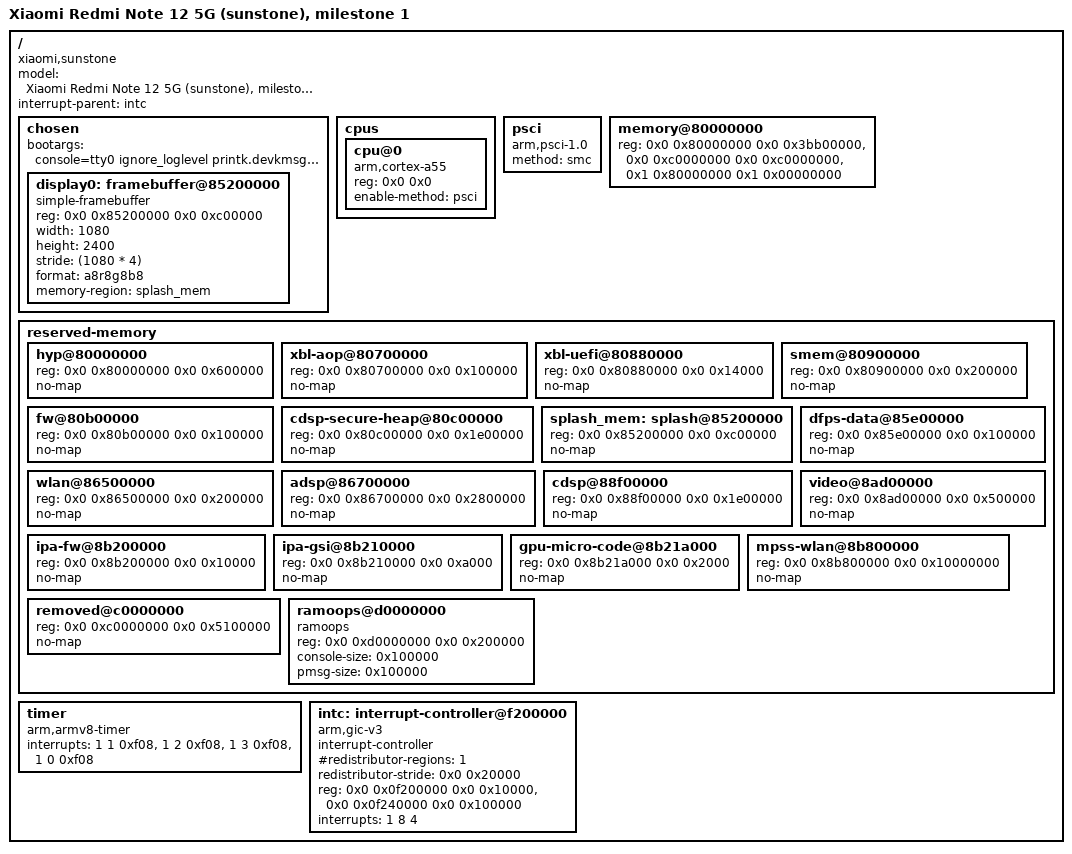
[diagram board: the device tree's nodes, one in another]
// SPDX-License-Identifier: BSD-3-Clause
/*
 * Xiaomi Redmi Note 12 5G (sunstone), SM4375 "blair": milestone 1 tree.
 *
 * Deliberately standalone (no sm6375.dtsi): one CPU, the GIC, the arch timer, RAM, the
 * firmware carve-outs, ABL's splash framebuffer and ramoops. No clock, power-domain or
 * regulator providers, so nothing switches off what the bootloader left running (the
 * panel keeps scanning the splash buffer). Values from the phone's live DT (2026-10-20).
 */
/dts-v1/;

/ {
	model = "Xiaomi Redmi Note 12 5G (sunstone), milestone 1";
	compatible = "xiaomi,sunstone", "qcom,sm4375";
	#address-cells = <2>;
	#size-cells = <2>;
	interrupt-parent = <&intc>;

	chosen {
		#address-cells = <2>;
		#size-cells = <2>;
		ranges;
		bootargs = "console=tty0 ignore_loglevel printk.devkmsg=on panic=20 reboot=warm rdinit=/init";

		display0: framebuffer@85200000 {
			compatible = "simple-framebuffer";
			reg = <0x0 0x85200000 0x0 0xc00000>;
			width = <1080>;
			height = <2400>;
			stride = <(1080 * 4)>;
			format = "a8r8g8b8";
			memory-region = <&splash_mem>;
		};
	};

	cpus {
		#address-cells = <2>;
		#size-cells = <0>;

		cpu@0 {
			device_type = "cpu";
			compatible = "arm,cortex-a55";
			reg = <0x0 0x0>;
			enable-method = "psci";
		};
	};

	psci {
		compatible = "arm,psci-1.0";
		method = "smc";
	};

	memory@80000000 {
		device_type = "memory";
		reg = <0x0 0x80000000 0x0 0x3bb00000>,
		      <0x0 0xc0000000 0x0 0xc0000000>,
		      <0x1 0x80000000 0x1 0x00000000>;
	};

	reserved-memory {
		#address-cells = <2>;
		#size-cells = <2>;
		ranges;

		hyp@80000000 { reg = <0x0 0x80000000 0x0 0x600000>; no-map; };
		xbl-aop@80700000 { reg = <0x0 0x80700000 0x0 0x100000>; no-map; };
		xbl-uefi@80880000 { reg = <0x0 0x80880000 0x0 0x14000>; no-map; };
		smem@80900000 { reg = <0x0 0x80900000 0x0 0x200000>; no-map; };
		fw@80b00000 { reg = <0x0 0x80b00000 0x0 0x100000>; no-map; };
		cdsp-secure-heap@80c00000 { reg = <0x0 0x80c00000 0x0 0x1e00000>; no-map; };
		splash_mem: splash@85200000 { reg = <0x0 0x85200000 0x0 0xc00000>; no-map; };
		dfps-data@85e00000 { reg = <0x0 0x85e00000 0x0 0x100000>; no-map; };
		wlan@86500000 { reg = <0x0 0x86500000 0x0 0x200000>; no-map; };
		adsp@86700000 { reg = <0x0 0x86700000 0x0 0x2800000>; no-map; };
		cdsp@88f00000 { reg = <0x0 0x88f00000 0x0 0x1e00000>; no-map; };
		video@8ad00000 { reg = <0x0 0x8ad00000 0x0 0x500000>; no-map; };
		ipa-fw@8b200000 { reg = <0x0 0x8b200000 0x0 0x10000>; no-map; };
		ipa-gsi@8b210000 { reg = <0x0 0x8b210000 0x0 0xa000>; no-map; };
		gpu-micro-code@8b21a000 { reg = <0x0 0x8b21a000 0x0 0x2000>; no-map; };
		mpss-wlan@8b800000 { reg = <0x0 0x8b800000 0x0 0x10000000>; no-map; };
		removed@c0000000 { reg = <0x0 0xc0000000 0x0 0x5100000>; no-map; };

		/* the downstream kernel's layout, so either kernel reads the other's records */
		ramoops@d0000000 {
			compatible = "ramoops";
			reg = <0x0 0xd0000000 0x0 0x200000>;
			console-size = <0x100000>;
			pmsg-size = <0x100000>;
		};
	};

	timer {
		compatible = "arm,armv8-timer";
		/* secure phys, non-secure phys, virtual, hypervisor PPIs; level low */
		interrupts = <1 1 0xf08>, <1 2 0xf08>, <1 3 0xf08>, <1 0 0xf08>;
	};

	intc: interrupt-controller@f200000 {
		compatible = "arm,gic-v3";
		#interrupt-cells = <3>;
		interrupt-controller;
		#redistributor-regions = <1>;
		redistributor-stride = <0x0 0x20000>;
		reg = <0x0 0x0f200000 0x0 0x10000>,
		      <0x0 0x0f240000 0x0 0x100000>;
		interrupts = <1 8 4>;
	};
};
